VERSION ""

NS_ :

BS_:

BU_: Device Host

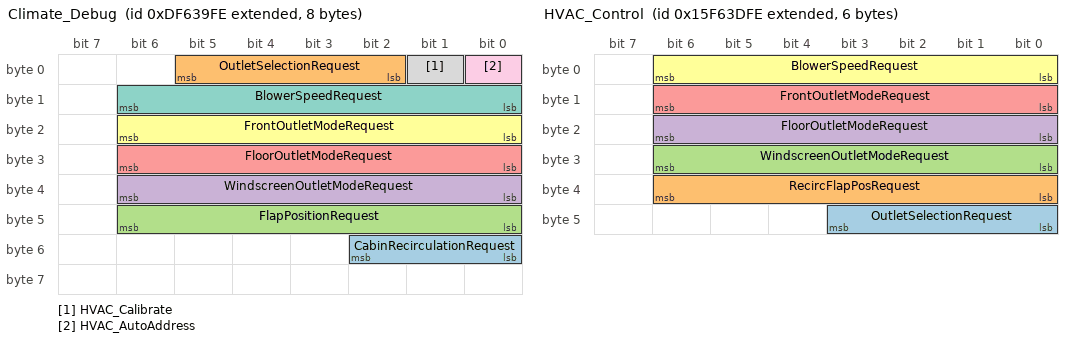
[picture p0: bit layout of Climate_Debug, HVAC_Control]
BO_ 2381724158 Climate_Debug: 8 Vector__XXX
 SG_ CabinRecirculationRequest : 48|3@1+ (1,0) [0|3] "" Vector__XXX
 SG_ OutletSelectionRequest : 2|4@1+ (1,0) [0|15] "" Vector__XXX
 SG_ FlapPositionRequest : 40|7@1+ (1,0) [0|100] "%" Vector__XXX
 SG_ WindscreenOutletModeRequest : 32|7@1+ (1,0) [0|100] "%" Vector__XXX
 SG_ FloorOutletModeRequest : 24|7@1+ (1,0) [0|100] "%" Vector__XXX
 SG_ FrontOutletModeRequest : 16|7@1+ (1,0) [0|100] "%" Vector__XXX
 SG_ BlowerSpeedRequest : 8|7@1+ (1,0) [0|100] "%" Vector__XXX
 SG_ HVAC_Calibrate : 1|1@1+ (1,0) [0|1] "" Vector__XXX
 SG_ HVAC_AutoAddress : 0|1@1+ (1,0) [0|1] "" Vector__XXX

BO_ 2381723902 HVAC_Feedback: 8 Vector__XXX
 SG_ OutletSelectionState : 48|4@1+ (1,0) [0|15] "" Vector__XXX
 SG_ RecircModeState : 52|3@1+ (1,0) [0|7] "" Vector__XXX
 SG_ BlowerSpeed : 40|7@1+ (1,0) [0|100] "%" Vector__XXX
 SG_ IsolationValveIntegrityFault : 29|1@1+ (1,0) [0|1] "" Vector__XXX
 SG_ WindscreenFlapIntegrityFault : 28|1@1+ (1,0) [0|1] "" Vector__XXX
 SG_ HVACActualLVPower : 56|7@1+ (1,0) [0|127] "W" Vector__XXX
 SG_ HVACFailure : 27|1@1+ (1,0) [0|1] "" Vector__XXX
 SG_ FrontFlapIntegrityFault : 26|1@1+ (1,0) [0|1] "" Vector__XXX
 SG_ FloorFlapIntegrityFault : 15|1@1+ (1,0) [0|1] "" Vector__XXX
 SG_ RecircFlapIntegrityFault : 14|1@1+ (1,0) [0|1] "" Vector__XXX
 SG_ BlowerIntegrityFault : 13|1@1+ (1,0) [0|1] "" Vector__XXX
 SG_ TAirOutSensorIntegrityFault : 12|1@1+ (1,0) [0|1] "" Vector__XXX
 SG_ TAirInSensorIntegrityFault : 11|1@1+ (1,0) [0|1] "" Vector__XXX
 SG_ TChillerCoreSensorIntegrityFault : 10|1@1+ (1,0) [0|1] "" Vector__XXX
 SG_ AirOutTemperature : 30|10@1+ (0.2,-50) [-50|154.6] "degC" Vector__XXX
 SG_ AirInTemperature : 16|10@1+ (0.2,-50) [-50|154.6] "degC" Vector__XXX
 SG_ ColdCoilTemperature : 0|10@1+ (0.2,-50) [-50|154.6] "degC" Vector__XXX

BO_ 2515945982 Reserved6: 8 Vector__XXX

BO_ 2515945470 Reserved5: 8 Vector__XXX

BO_ 2515945214 Reserved4: 8 Vector__XXX

BO_ 2515944958 Reserved1: 8 Vector__XXX

BO_ 2515944702 Reserved3: 8 Vector__XXX

BO_ 2515944446 Reserved2: 8 Vector__XXX

BO_ 2515943166 Reserved7: 8 Vector__XXX

BO_ 2515942910 HVAC_Control: 6 Vector__XXX
 SG_ OutletSelectionRequest : 40|4@1+ (1,0) [0|15] "" Vector__XXX
 SG_ RecircFlapPosRequest : 32|7@1+ (1,0) [0|100] "%" Vector__XXX
 SG_ WindscreenOutletModeRequest : 24|7@1+ (1,0) [0|100] "%" Vector__XXX
 SG_ FloorOutletModeRequest : 16|7@1+ (1,0) [0|100] "%" Vector__XXX
 SG_ FrontOutletModeRequest : 8|7@1+ (1,0) [0|100] "%" Vector__XXX
 SG_ BlowerSpeedRequest : 0|7@1+ (1,0) [0|100] "%" Vector__XXX

CM_ "$File: //depot/auto/dbc/StaticInternal/TMS/Climate/0.1.0.0/Climate_int.dbc $
$Change: 215788 $
$DateTime: 2024/08/14 11:00:28 $
$Revision: #1 $";
CM_ BO_ 2515945982 "Cabin Climate HVAC Request";
CM_ BO_ 2515945470 "Cabin Climate HVAC Request";
CM_ BO_ 2515945214 "Cabin Climate HVAC Request";
CM_ BO_ 2515944958 "Cabin Climate HVAC Request";
CM_ BO_ 2515944702 "Cabin Climate HVAC Request";
CM_ BO_ 2515944446 "Cabin Climate HVAC Request";
CM_ BO_ 2515943166 "Cabin Climate HVAC Request";
CM_ BO_ 2515942910 "Cabin Climate HVAC Request";
BA_DEF_  "BusType" STRING ;
BA_DEF_  "DBName" STRING ;
BA_DEF_  "DatabaseVersion" STRING ;
BA_DEF_ BO_  "GenMsgCycleTime" INT 0 3600000;
BA_DEF_ BO_  "GenMsgILSupport" ENUM  "No","Yes";
BA_DEF_ BO_  "GenMsgRequestable" INT 0 1;
BA_DEF_ BO_  "GenMsgSendType" ENUM  "cyclic","NotUsed","NotUsed","NotUsed","NotUsed","NotUsed","NotUsed","IfActive","noMsgSendType";
BA_DEF_ SG_  "GenSigEVName" STRING ;
BA_DEF_ SG_  "GenSigILSupport" ENUM  "No","Yes";
BA_DEF_ SG_  "GenSigSendType" ENUM  "Cyclic","OnWrite","OnWriteWithRepetition","OnChange","OnChangeWithRepetition","IfActive","IfActiveWithRepetition","NoSigSendType";
BA_DEF_ SG_  "GenSigStartValue" INT 0 2147483647;
BA_DEF_ BU_  "NmStationAddress" INT 0 255;
BA_DEF_  "ProtocolType" STRING ;
BA_DEF_  "SAE_J1939_21_SpecVersion" STRING ;
BA_DEF_  "SAE_J1939_71_SpecVersion" STRING ;
BA_DEF_  "SAE_J1939_73_SpecVersion" STRING ;
BA_DEF_  "SAE_J1939_75_SpecVersion" STRING ;
BA_DEF_  "SAE_J1939_81_SpecVersion" STRING ;
BA_DEF_  "SAE_J1939_DA_SpecVersion" STRING ;
BA_DEF_ BO_  "Producer" STRING ;
BA_DEF_ SG_  "SigType" ENUM  "Default","Range","RangeSigned","ASCII","Discrete","Control","ReferencePGN","DTC","StringDelimiter","StringLength","StringLengthControl","MessageCounter","MessageChecksum";
BA_DEF_ BO_  "VFrameFormat" ENUM  "StandardCAN","ExtendedCAN","reserved","J1939PG","reserved","reserved","reserved","reserved","reserved","reserved","reserved","reserved","reserved","reserved","StandardCAN_FD","ExtendedCAN_FD";
BA_DEF_DEF_  "BusType" "";
BA_DEF_DEF_  "DBName" "Climate_int";
BA_DEF_DEF_  "DatabaseVersion" "";
BA_DEF_DEF_  "GenMsgCycleTime" 0;
BA_DEF_DEF_  "GenMsgILSupport" "Yes";
BA_DEF_DEF_  "GenMsgRequestable" 1;
BA_DEF_DEF_  "GenMsgSendType" "noMsgSendType";
BA_DEF_DEF_  "GenSigEVName" "Env@Nodename_@Signame";
BA_DEF_DEF_  "GenSigILSupport" "Yes";
BA_DEF_DEF_  "GenSigSendType" "NoSigSendType";
BA_DEF_DEF_  "GenSigStartValue" 0;
BA_DEF_DEF_  "NmStationAddress" 254;
BA_DEF_DEF_  "ProtocolType" "";
BA_DEF_DEF_  "SAE_J1939_21_SpecVersion" "";
BA_DEF_DEF_  "SAE_J1939_71_SpecVersion" "";
BA_DEF_DEF_  "SAE_J1939_73_SpecVersion" "";
BA_DEF_DEF_  "SAE_J1939_75_SpecVersion" "";
BA_DEF_DEF_  "SAE_J1939_81_SpecVersion" "";
BA_DEF_DEF_  "SAE_J1939_DA_SpecVersion" "";
BA_DEF_DEF_  "Producer" "TMS";
BA_DEF_DEF_  "SigType" "Default";
BA_DEF_DEF_  "VFrameFormat" "J1939PG";
BA_ "SAE_J1939_DA_SpecVersion" "2015-01";
BA_ "SAE_J1939_81_SpecVersion" "2012-05";
BA_ "SAE_J1939_75_SpecVersion" "2012-05";
BA_ "SAE_J1939_73_SpecVersion" "2012-10";
BA_ "SAE_J1939_71_SpecVersion" "2012-10";
BA_ "SAE_J1939_21_SpecVersion" "2006-10";
BA_ "ProtocolType" "J1939";
BA_ "DatabaseVersion" "1.0";
BA_ "BusType" "CAN";
BA_ "GenMsgSendType" BO_ 2381724158 0;
BA_ "GenMsgCycleTime" BO_ 2381724158 1000;
BA_ "GenMsgCycleTime" BO_ 2381723902 250;
BA_ "GenMsgSendType" BO_ 2381723902 0;
BA_ "GenMsgSendType" BO_ 2515945982 0;
BA_ "GenMsgCycleTime" BO_ 2515945982 250;
BA_ "GenMsgSendType" BO_ 2515945470 0;
BA_ "GenMsgCycleTime" BO_ 2515945470 250;
BA_ "GenMsgSendType" BO_ 2515945214 0;
BA_ "GenMsgCycleTime" BO_ 2515945214 250;
BA_ "GenMsgSendType" BO_ 2515944958 0;
BA_ "GenMsgCycleTime" BO_ 2515944958 250;
BA_ "GenMsgSendType" BO_ 2515944702 0;
BA_ "GenMsgCycleTime" BO_ 2515944702 250;
BA_ "GenMsgSendType" BO_ 2515944446 0;
BA_ "GenMsgCycleTime" BO_ 2515944446 250;
BA_ "GenMsgSendType" BO_ 2515943166 0;
BA_ "GenMsgCycleTime" BO_ 2515943166 100;
BA_ "GenMsgSendType" BO_ 2515942910 0;
BA_ "GenMsgCycleTime" BO_ 2515942910 100;
BA_ "GenSigStartValue" SG_ 2381724158 CabinRecirculationRequest 7;
BA_ "GenSigStartValue" SG_ 2381723902 OutletSelectionState 15;
BA_ "GenSigStartValue" SG_ 2381723902 RecircModeState 7;
BA_ "GenSigStartValue" SG_ 2381723902 AirOutTemperature 500;
BA_ "GenSigStartValue" SG_ 2381723902 AirInTemperature 500;
BA_ "GenSigStartValue" SG_ 2381723902 ColdCoilTemperature 500;
VAL_ 2381724158 CabinRecirculationRequest 7 "NA" 6 "Error" 2 "Auto" 1 "FullRecirc" 0 "Fresh" ;
VAL_ 2381724158 OutletSelectionRequest 15 "NA" 14 "Error" 8 "Auto" 6 "Windscreen/Front" 7 "Windscreen/Front/Floor" 5 "Windscreen/Floor" 4 "Front/Floor" 3 "Floor" 2 "Front" 1 "Windscreen" 0 "Off" ;
VAL_ 2381723902 OutletSelectionState 15 "NA" 14 "Error" 8 "Auto" 6 "Windscreen/Front" 7 "Windscreen/Front/Floor" 5 "Windscreen/Floor" 4 "Front/Floor" 3 "Floor" 2 "Front" 1 "Windscreen" 0 "Off" ;
VAL_ 2381723902 RecircModeState 7 "NA" 6 "Error" 2 "Auto" 1 "FullRecirc" 0 "Fresh" ;
VAL_ 2515942910 OutletSelectionRequest 15 "NA" 14 "Error" 8 "Auto" 6 "Windscreen/Front" 7 "Windscreen/Front/Floor" 5 "Windscreen/Floor" 4 "Front/Floor" 3 "Floor" 2 "Front" 1 "Windscreen" 0 "Off" ;
